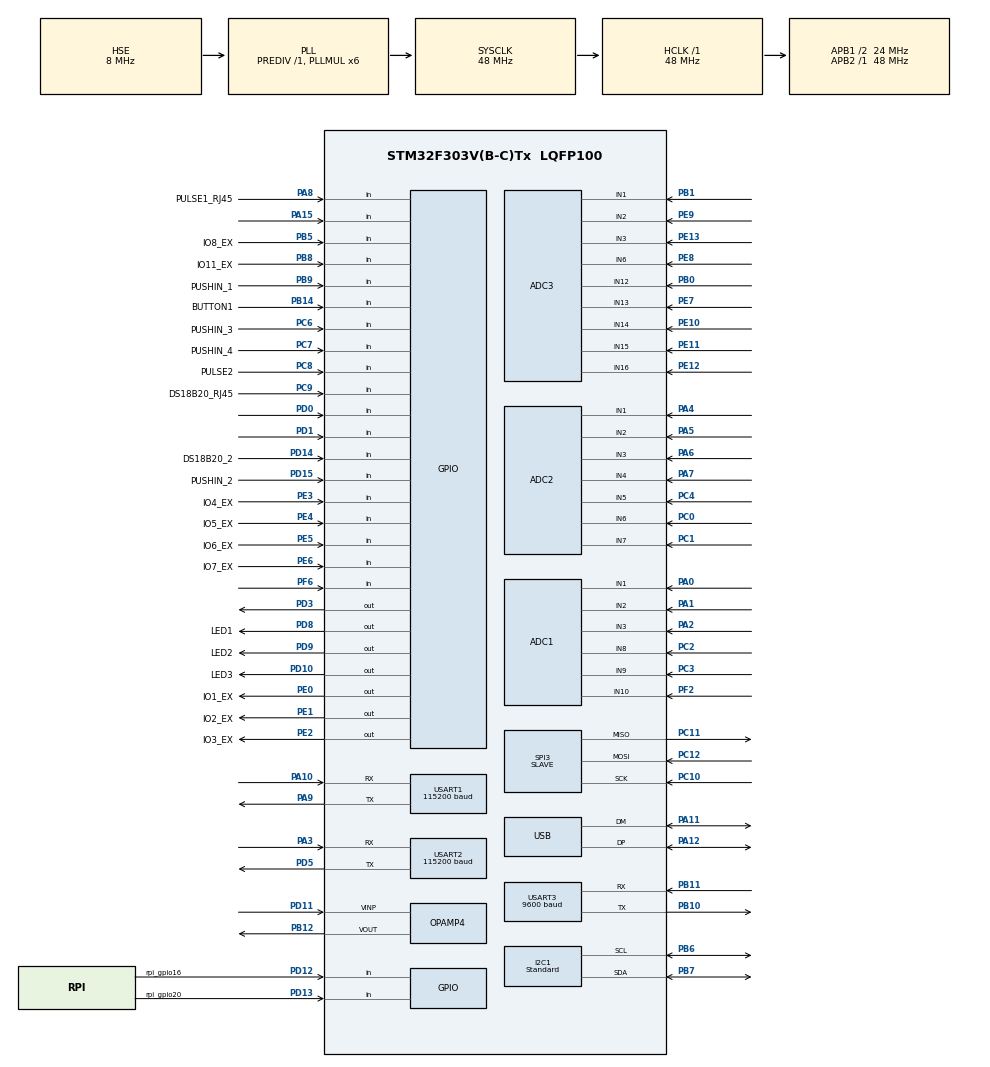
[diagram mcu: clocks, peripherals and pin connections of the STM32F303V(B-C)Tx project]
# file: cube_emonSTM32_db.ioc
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ADC1.Channel-3\#ChannelRegularConversion=ADC_CHANNEL_1
ADC1.NbrOfConversionFlag=1
ADC1.Offset-3\#ChannelRegularConversion=0
ADC1.OffsetNumber-3\#ChannelRegularConversion=ADC_OFFSET_NONE
ADC1.Rank-3\#ChannelRegularConversion=1
ADC1.SamplingTime-3\#ChannelRegularConversion=ADC_SAMPLETIME_1CYCLE_5
ADC1.master=1
ADC2.Channel-1\#ChannelRegularConversion=ADC_CHANNEL_1
ADC2.NbrOfConversionFlag=1
ADC2.Offset-1\#ChannelRegularConversion=0
ADC2.OffsetNumber-1\#ChannelRegularConversion=ADC_OFFSET_NONE
ADC2.Rank-1\#ChannelRegularConversion=1
ADC2.SamplingTime-1\#ChannelRegularConversion=ADC_SAMPLETIME_1CYCLE_5
ADC3.Channel-2\#ChannelRegularConversion=ADC_CHANNEL_2
ADC3.NbrOfConversionFlag=1
ADC3.Offset-2\#ChannelRegularConversion=0
ADC3.OffsetNumber-2\#ChannelRegularConversion=ADC_OFFSET_NONE
ADC3.Rank-2\#ChannelRegularConversion=1
ADC3.SamplingTime-2\#ChannelRegularConversion=ADC_SAMPLETIME_1CYCLE_5
ADC3.master=1
ADC4.Channel-2\#ChannelRegularConversion=ADC_CHANNEL_VOPAMP4
ADC4.NbrOfConversionFlag=1
ADC4.Offset-2\#ChannelRegularConversion=0
ADC4.OffsetNumber-2\#ChannelRegularConversion=ADC_OFFSET_NONE
ADC4.Rank-2\#ChannelRegularConversion=1
ADC4.SamplingTime-2\#ChannelRegularConversion=ADC_SAMPLETIME_1CYCLE_5
I2C1.I2C_Speed_Mode=I2C_Standard
I2C1.Speed=50
I2C1.Timing=0x00101D7C
Mcu.Family=STM32F3
Mcu.Name=STM32F303V(B-C)Tx
Mcu.Package=LQFP100
NVIC.PriorityGroup=NVIC_PRIORITYGROUP_4
NVIC.USB_LP_CAN_RX0_IRQn=true\:0\:0\:false\:false\:true\:false\:true
PA0.Mode=IN1-Single-Ended
PA0.Signal=ADC1_IN1
PA1.Mode=IN2-Single-Ended
PA1.Signal=ADC1_IN2
PA10.Mode=Asynchronous
PA10.Signal=USART1_RX
PA11.Mode=Device
PA11.Signal=USB_DM
PA12.GPIO_PuPd=GPIO_PULLUP
PA12.Mode=Device
PA12.Signal=USB_DP
PA13.Mode=Serial_Wire
PA13.Signal=SYS_JTMS-SWDIO
PA14.Mode=Serial_Wire
PA14.Signal=SYS_JTCK-SWCLK
PA15.Signal=GPIO_Input
PA2.Mode=IN3-Single-Ended
PA2.Signal=ADC1_IN3
PA3.Mode=Asynchronous
PA3.Signal=USART2_RX
PA4.Mode=IN1-Single-Ended
PA4.Signal=ADC2_IN1
PA5.Mode=IN2-Single-Ended
PA5.Signal=ADC2_IN2
PA6.Mode=IN3-Single-Ended
PA6.Signal=ADC2_IN3
PA7.Mode=IN4-Single-Ended
PA7.Signal=ADC2_IN4
PA8.GPIO_Label=PULSE1_RJ45
PA8.Signal=GPIO_Input
PA9.Mode=Asynchronous
PA9.Signal=USART1_TX
PB0.Mode=IN12-Single-Ended
PB0.Signal=ADC3_IN12
PB1.Mode=IN1-Single-Ended
PB1.Signal=ADC3_IN1
PB10.Mode=Asynchronous
PB10.Signal=USART3_TX
PB11.Mode=Asynchronous
PB11.Signal=USART3_RX
PB12.Mode=Follower
PB12.Signal=OPAMP4_VOUT
PB14.GPIO_Label=BUTTON1
PB14.Signal=GPIO_Input
PB5.GPIO_Label=IO8_EX
PB5.Signal=GPIO_Input
PB6.Mode=I2C
PB6.Signal=I2C1_SCL
PB7.Mode=I2C
PB7.Signal=I2C1_SDA
PB8.GPIO_Label=IO11_EX
PB8.Signal=GPIO_Input
PB9.GPIO_Label=PUSHIN_1
PB9.Signal=GPIO_Input
PC0.Signal=ADCx_IN6
PC1.Signal=ADCx_IN7
PC10.Mode=Full_Duplex_Slave
PC10.Signal=SPI3_SCK
PC11.Mode=Full_Duplex_Slave
PC11.Signal=SPI3_MISO
PC12.Mode=Full_Duplex_Slave
PC12.Signal=SPI3_MOSI
PC14-OSC32_IN.Mode=LSE-External-Oscillator
PC14-OSC32_IN.Signal=RCC_OSC32_IN
PC15-OSC32_OUT.Mode=LSE-External-Oscillator
PC15-OSC32_OUT.Signal=RCC_OSC32_OUT
PC2.Signal=ADCx_IN8
PC3.Signal=ADCx_IN9
PC4.Mode=IN5-Single-Ended
PC4.Signal=ADC2_IN5
PC6.GPIO_Label=PUSHIN_3
PC6.Signal=GPIO_Input
PC7.GPIO_Label=PUSHIN_4
PC7.Signal=GPIO_Input
PC8.GPIO_Label=PULSE2
PC8.Signal=GPIO_Input
PC9.GPIO_Label=DS18B20_RJ45
PC9.Signal=GPIO_Input
PD0.Signal=GPIO_Input
PD1.Signal=GPIO_Input
PD10.GPIO_Label=LED3
PD10.Signal=GPIO_Output
PD11.Mode=Follower
PD11.Signal=OPAMP4_VINP
PD12.GPIO_Label=rpi_gpio16
PD12.Signal=GPIO_Input
PD13.GPIO_Label=rpi_gpio20
PD13.Signal=GPIO_Input
PD14.GPIO_Label=DS18B20_2
PD14.Signal=GPIO_Input
PD15.GPIO_Label=PUSHIN_2
PD15.Signal=GPIO_Input
PD3.Signal=GPIO_Output
PD5.Mode=Asynchronous
PD5.Signal=USART2_TX
PD8.GPIO_Label=LED1
PD8.Signal=GPIO_Output
PD9.GPIO_Label=LED2
PD9.Signal=GPIO_Output
PE0.GPIO_Label=IO1_EX
PE0.Signal=GPIO_Output
PE1.GPIO_Label=IO2_EX
PE1.Signal=GPIO_Output
PE10.Mode=IN14-Single-Ended
PE10.Signal=ADC3_IN14
PE11.Mode=IN15-Single-Ended
PE11.Signal=ADC3_IN15
PE12.Mode=IN16-Single-Ended
PE12.Signal=ADC3_IN16
PE13.Mode=IN3-Single-Ended
PE13.Signal=ADC3_IN3
PE2.GPIO_Label=IO3_EX
PE2.Signal=GPIO_Output
PE3.GPIO_Label=IO4_EX
PE3.Signal=GPIO_Input
PE4.GPIO_Label=IO5_EX
PE4.Signal=GPIO_Input
PE5.GPIO_Label=IO6_EX
PE5.Signal=GPIO_Input
PE6.GPIO_Label=IO7_EX
PE6.Signal=GPIO_Input
PE7.Mode=IN13-Single-Ended
PE7.Signal=ADC3_IN13
PE8.Signal=ADCx_IN6P
PE9.Mode=IN2-Single-Ended
PE9.Signal=ADC3_IN2
PF0-OSC_IN.Mode=HSE-External-Oscillator
PF0-OSC_IN.Signal=RCC_OSC_IN
PF1-OSC_OUT.Mode=HSE-External-Oscillator
PF1-OSC_OUT.Signal=RCC_OSC_OUT
PF2.Signal=ADCx_IN10
PF6.Signal=GPIO_Input
ProjectManager.HeapSize=0x200
ProjectManager.StackSize=0x400
ProjectManager.TargetToolchain=Makefile
RCC.ADC12PRES=RCC_ADC12PLLCLK_DIV4
RCC.ADC34PRES=RCC_ADC34PLLCLK_DIV4
RCC.AHBFreq_Value=48000000
RCC.APB1CLKDivider=RCC_HCLK_DIV2
RCC.APB1Freq_Value=24000000
RCC.APB1TimFreq_Value=48000000
RCC.APB2Freq_Value=48000000
RCC.APB2TimFreq_Value=48000000
RCC.CortexFreq_Value=48000000
RCC.HCLKFreq_Value=48000000
RCC.HSE_VALUE=8000000
RCC.HSI_VALUE=8000000
RCC.PLLMUL=RCC_PLL_MUL6
RCC.PREFETCH_ENABLE=1
RCC.SYSCLKFreq_VALUE=48000000
RCC.SYSCLKSourceVirtual=RCC_SYSCLKSOURCE_PLLCLK
RCC.USBFreq_Value=48000000
RCC.Usart1ClockSelection=RCC_USART1CLKSOURCE_SYSCLK
RCC.Usart2ClockSelection=RCC_USART2CLKSOURCE_SYSCLK
RCC.Usart3ClockSelection=RCC_USART3CLKSOURCE_SYSCLK
SH.ADCx_IN10.0=ADC1_IN10,IN10-Single-Ended
SH.ADCx_IN6.0=ADC2_IN6,IN6-Single-Ended
SH.ADCx_IN6P.0=ADC3_IN6,IN6-Single-Ended
SH.ADCx_IN7.0=ADC2_IN7,IN7-Single-Ended
SH.ADCx_IN8.0=ADC1_IN8,IN8-Single-Ended
SH.ADCx_IN9.0=ADC1_IN9,IN9-Single-Ended
SPI3.DataSize=SPI_DATASIZE_8BIT
SPI3.Direction=SPI_DIRECTION_2LINES
SPI3.Mode=SPI_MODE_SLAVE
SPI3.VirtualType=VM_SLAVE
USART1.BaudRate=115200
USART1.VirtualMode-Asynchronous=VM_ASYNC
USART2.BaudRate=115200
USART2.VirtualMode-Asynchronous=VM_ASYNC
USART3.BaudRate=9600
USART3.VirtualMode-Asynchronous=VM_ASYNC
USB_DEVICE.CLASS_NAME_FS=DFU
USB_DEVICE.VirtualMode=Dfu
USB_DEVICE.VirtualModeFS=Dfu_FS
VP_ADC4_OPAMP_INTERNAL4.Mode=IN-OPAMP4
VP_USB_DEVICE_VS_USB_DEVICE_DFU_FS.Mode=DFU_FS
board=custom

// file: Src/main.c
/* USER CODE BEGIN Header */
/**
  ******************************************************************************
  * @file           : main.c
  * @brief          : Main program body
  ******************************************************************************
  * @attention
  *
  * <h2><center>&copy; Copyright (c) 2019 STMicroelectronics.
  * All rights reserved.</center></h2>
  *
  * This software component is licensed by ST under BSD 3-Clause license,
  * the "License"; You may not use this file except in compliance with the
  * License. You may obtain a copy of the License at:
  *                        opensource.org/licenses/BSD-3-Clause
  *
  ******************************************************************************
  */
/* USER CODE END Header */

#include "main.h"
#include "adc.h"
#include "i2c.h"
#include "opamp.h"
#include "spi.h"
#include "usart.h"
#include "usb_device.h"
#include "gpio.h"

/* USER CODE BEGIN PV */
char log_buffer[100];
/* USER CODE END PV */

void SystemClock_Config(void);

int main(void)
{

  /* MCU Configuration--------------------------------------------------------*/

  /* Reset of all peripherals, Initializes the Flash interface and the Systick. */
  HAL_Init();

  /* Configure the system clock */
  SystemClock_Config();

  /* Initialize all configured peripherals */
  MX_GPIO_Init();
  MX_ADC1_Init();
  MX_ADC2_Init();
  MX_ADC3_Init();
  MX_ADC4_Init();
  MX_USART1_UART_Init();
  MX_USART3_UART_Init();
  MX_I2C1_Init();
  MX_OPAMP4_Init();
  MX_USB_DEVICE_Init();
  MX_USART2_UART_Init();
  MX_SPI3_Init();
  /* USER CODE BEGIN 2 */

  unsigned long previousMillis = 0;
  const long interval = 2000;

  sprintf(log_buffer, "Hello World\r\n");
  debug_printf(log_buffer);

  uint8_t uart_buff[1] = {0};
  //char RxCounter = 0;

  /* USER CODE END 2 */

  /* Infinite loop */
  /* USER CODE BEGIN WHILE */
  while (1)
 {
    HAL_UART_Receive(&huart1, *uart_buff, sizeof(uart_buff), 100);

    //sprintf(log_buffer, "Character is %c \n\r", uart_buff);
    //debug_printf(log_buffer);

    unsigned long currentMillis = HAL_GetTick();
    if (currentMillis - previousMillis >= interval)
    {
      previousMillis = currentMillis;

      // LEDs
      HAL_GPIO_TogglePin(GPIOD, GPIO_PIN_8);
      HAL_GPIO_TogglePin(GPIOD, GPIO_PIN_9);
      HAL_GPIO_TogglePin(GPIOD, GPIO_PIN_10);

      sprintf(log_buffer, "buff %s\r\n", uart_buff);
      debug_printf(log_buffer);
      sprintf(log_buffer, "Hello World\r\n");
      debug_printf(log_buffer);
    }

    /* USER CODE END WHILE */

  }
}

void SystemClock_Config(void)
{
  RCC_OscInitTypeDef RCC_OscInitStruct = {0};
  RCC_ClkInitTypeDef RCC_ClkInitStruct = {0};
  RCC_PeriphCLKInitTypeDef PeriphClkInit = {0};

  /** Initializes the CPU, AHB and APB busses clocks
  */
  RCC_OscInitStruct.OscillatorType = RCC_OSCILLATORTYPE_HSI|RCC_OSCILLATORTYPE_HSE;
  RCC_OscInitStruct.HSEState = RCC_HSE_ON;
  RCC_OscInitStruct.HSEPredivValue = RCC_HSE_PREDIV_DIV1;
  RCC_OscInitStruct.HSIState = RCC_HSI_ON;
  RCC_OscInitStruct.HSICalibrationValue = RCC_HSICALIBRATION_DEFAULT;
  RCC_OscInitStruct.PLL.PLLState = RCC_PLL_ON;
  RCC_OscInitStruct.PLL.PLLSource = RCC_PLLSOURCE_HSE;
  RCC_OscInitStruct.PLL.PLLMUL = RCC_PLL_MUL6;
  if (HAL_RCC_OscConfig(&RCC_OscInitStruct) != HAL_OK)
  {
    Error_Handler();
  }
  /** Initializes the CPU, AHB and APB busses clocks
  */
  RCC_ClkInitStruct.ClockType = RCC_CLOCKTYPE_HCLK|RCC_CLOCKTYPE_SYSCLK
                              |RCC_CLOCKTYPE_PCLK1|RCC_CLOCKTYPE_PCLK2;
  RCC_ClkInitStruct.SYSCLKSource = RCC_SYSCLKSOURCE_PLLCLK;
  RCC_ClkInitStruct.AHBCLKDivider = RCC_SYSCLK_DIV1;
  RCC_ClkInitStruct.APB1CLKDivider = RCC_HCLK_DIV2;
  RCC_ClkInitStruct.APB2CLKDivider = RCC_HCLK_DIV1;

  if (HAL_RCC_ClockConfig(&RCC_ClkInitStruct, FLASH_LATENCY_1) != HAL_OK)
  {
    Error_Handler();
  }
  PeriphClkInit.PeriphClockSelection = RCC_PERIPHCLK_USB|RCC_PERIPHCLK_USART1
                              |RCC_PERIPHCLK_USART2|RCC_PERIPHCLK_USART3
                              |RCC_PERIPHCLK_I2C1|RCC_PERIPHCLK_ADC12
                              |RCC_PERIPHCLK_ADC34;
  PeriphClkInit.Usart1ClockSelection = RCC_USART1CLKSOURCE_SYSCLK;
  PeriphClkInit.Usart2ClockSelection = RCC_USART2CLKSOURCE_SYSCLK;
  PeriphClkInit.Usart3ClockSelection = RCC_USART3CLKSOURCE_SYSCLK;
  PeriphClkInit.Adc12ClockSelection = RCC_ADC12PLLCLK_DIV4;
  PeriphClkInit.Adc34ClockSelection = RCC_ADC34PLLCLK_DIV4;
  PeriphClkInit.I2c1ClockSelection = RCC_I2C1CLKSOURCE_HSI;
  PeriphClkInit.USBClockSelection = RCC_USBCLKSOURCE_PLL;
  if (HAL_RCCEx_PeriphCLKConfig(&PeriphClkInit) != HAL_OK)
  {
    Error_Handler();
  }
}

void Error_Handler(void)
{
}

/************************ (C) COPYRIGHT STMicroelectronics *****END OF FILE****/
